# CC1311P3 register map
File version: 1.0
CPU: CM4 1.0, other endian, MPU, FPU, 3 interrupt priority bits
Registers are 32-bit, read-write, reset 0x0 unless marked. A register's access mark holds for its fields unless they carry their own. Offsets are from the block's base; [hi:lo] are bit positions; {n}, {i} and the like mark numbered series; 'fields as' and 'values as' point back to an identical list.

## FLASH — Flash sub-system registers, includes the Flash Memory Controller (FMC), flash read path, and an integrated Efuse controller and EFUSEROM.
Base 0x40030000
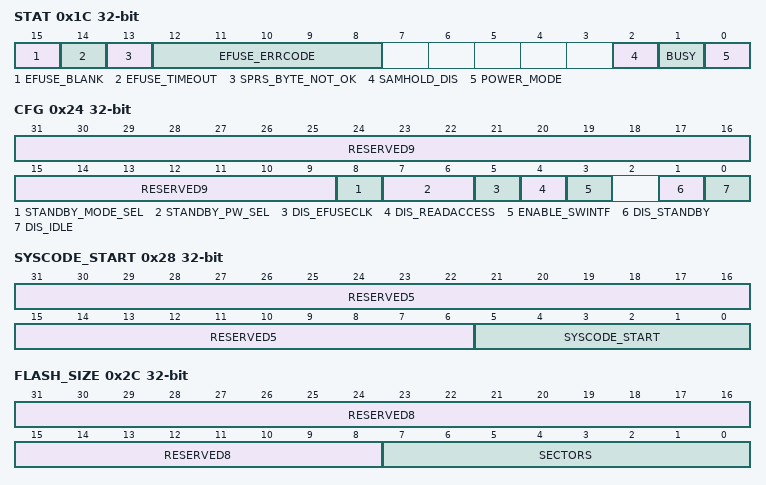
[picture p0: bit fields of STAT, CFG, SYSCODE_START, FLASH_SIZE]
0x1C STAT — FMC and Efuse Status
  [15] EFUSE_BLANK ro — [15:15] Efuse scanning detected if fuse ROM is blank: 0 : Not blank 1 : Blank
  [14] EFUSE_TIMEOUT ro — [14:14] Efuse scanning resulted in timeout error. 0 : No Timeout error 1 : Timeout Error
  [13] SPRS_BYTE_NOT_OK ro — [13:13] Efuse scanning resulted in scan chain Sparse byte error. 0 : No Sparse error 1 : Sparse Error
  [12:8] EFUSE_ERRCODE ro — [12:8] Same as EFUSEERROR.CODE
  [2] SAMHOLD_DIS ro — [2:2] Status indicator of flash sample and hold sequencing logic. This bit will go to 1 some delay after CFG.DIS_IDLE is set to 1. 0: Not disabled 1: Sample and hold disabled and stable
  [1] BUSY ro — [1:1] Fast version of the FMC FMSTAT.BUSY bit. This flag is valid immediately after the operation setting it (FMSTAT.BUSY is delayed some cycles) 0 : Not busy 1 : Busy
  [0] POWER_MODE ro — [0:0] Power state of the flash sub-system. 0 : Active 1 : Low power
0x24 CFG — Internal. Only to be used through TI provided API.
  [31:9] RESERVED9 — [31:9] Internal. Only to be used through TI provided API.
  [8] STANDBY_MODE_SEL — [8:8] Internal. Only to be used through TI provided API.
  [7:6] STANDBY_PW_SEL — [7:6] Internal. Only to be used through TI provided API.
  [5] DIS_EFUSECLK — [5:5] Internal. Only to be used through TI provided API.
  [4] DIS_READACCESS — [4:4] Internal. Only to be used through TI provided API.
  [3] ENABLE_SWINTF — [3:3] Internal. Only to be used through TI provided API.
  [1] DIS_STANDBY — [1:1] Internal. Only to be used through TI provided API.
  [0] DIS_IDLE — [0:0] Internal. Only to be used through TI provided API.
0x28 SYSCODE_START — Internal. Only to be used through TI provided API.
  [31:6] RESERVED5 ro — [31:6] Internal. Only to be used through TI provided API.
  [5:0] SYSCODE_START — [5:0] Internal. Only to be used through TI provided API.
0x2C FLASH_SIZE — Internal. Only to be used through TI provided API.
  [31:8] RESERVED8 ro — [31:8] Internal. Only to be used through TI provided API.
  [7:0] SECTORS — [7:0] Internal. Only to be used through TI provided API.
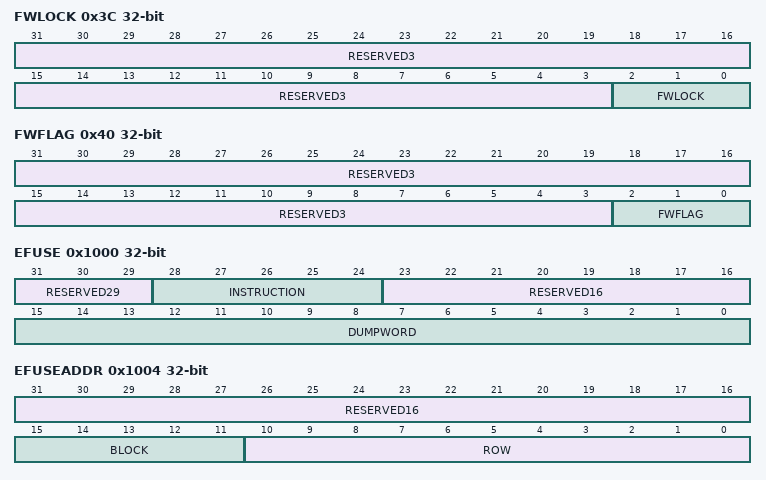
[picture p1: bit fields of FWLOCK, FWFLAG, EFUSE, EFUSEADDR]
0x3C FWLOCK — Internal. Only to be used through TI provided API.
  [31:3] RESERVED3 ro — [31:3] Internal. Only to be used through TI provided API.
  [2:0] FWLOCK — [2:0] Internal. Only to be used through TI provided API.
0x40 FWFLAG — Internal. Only to be used through TI provided API.
  [31:3] RESERVED3 ro — [31:3] Internal. Only to be used through TI provided API.
  [2:0] FWFLAG — [2:0] Internal. Only to be used through TI provided API.
0x1000 EFUSE — Internal. Only to be used through TI provided API.
  [31:29] RESERVED29 ro — [31:29] Internal. Only to be used through TI provided API.
  [28:24] INSTRUCTION — [28:24] Internal. Only to be used through TI provided API.
  [23:16] RESERVED16 ro — [23:16] Internal. Only to be used through TI provided API.
  [15:0] DUMPWORD — [15:0] Internal. Only to be used through TI provided API.
0x1004 EFUSEADDR — Internal. Only to be used through TI provided API.
  [31:16] RESERVED16 ro — [31:16] Internal. Only to be used through TI provided API.
  [15:11] BLOCK — [15:11] Internal. Only to be used through TI provided API.
  [10:0] ROW — [10:0] Internal. Only to be used through TI provided API.
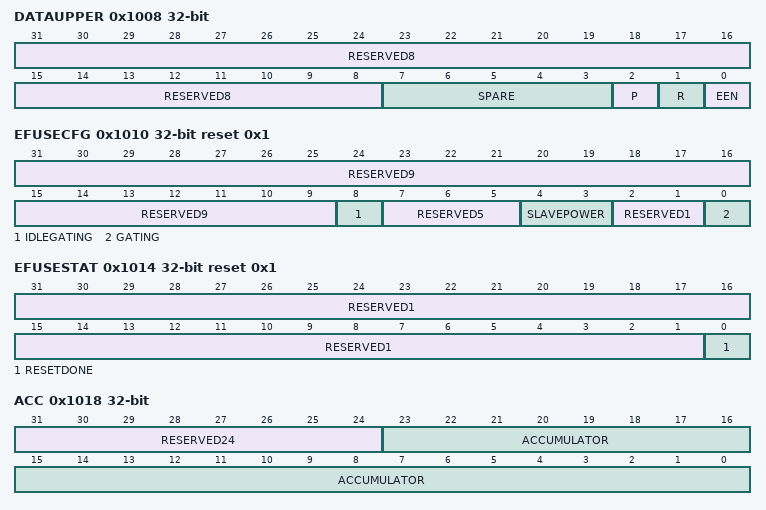
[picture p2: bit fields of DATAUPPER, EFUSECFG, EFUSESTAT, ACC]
0x1008 DATAUPPER — Internal. Only to be used through TI provided API.
  [31:8] RESERVED8 ro — [31:8] Internal. Only to be used through TI provided API.
  [7:3] SPARE — [7:3] Internal. Only to be used through TI provided API.
  [2] P — [2:2] Internal. Only to be used through TI provided API.
  [1] R — [1:1] Internal. Only to be used through TI provided API.
  [0] EEN — [0:0] Internal. Only to be used through TI provided API.
0x100C DATALOWER — Internal. Only to be used through TI provided API.
  [31:0] DATA — [31:0] Internal. Only to be used through TI provided API.
0x1010 EFUSECFG reset 0x1 — Internal. Only to be used through TI provided API.
  [31:9] RESERVED9 ro — [31:9] Internal. Only to be used through TI provided API.
  [8] IDLEGATING — [8:8] Internal. Only to be used through TI provided API.
  [7:5] RESERVED5 ro — [7:5] Internal. Only to be used through TI provided API.
  [4:3] SLAVEPOWER — [4:3] Internal. Only to be used through TI provided API.
  [2:1] RESERVED1 ro — [2:1] Internal. Only to be used through TI provided API.
  [0] GATING — [0:0] Internal. Only to be used through TI provided API.
0x1014 EFUSESTAT reset 0x1 — Internal. Only to be used through TI provided API.
  [31:1] RESERVED1 ro — [31:1] Internal. Only to be used through TI provided API.
  [0] RESETDONE ro — [0:0] Internal. Only to be used through TI provided API.
0x1018 ACC — Internal. Only to be used through TI provided API.
  [31:24] RESERVED24 ro — [31:24] Internal. Only to be used through TI provided API.
  [23:0] ACCUMULATOR ro — [23:0] Internal. Only to be used through TI provided API.
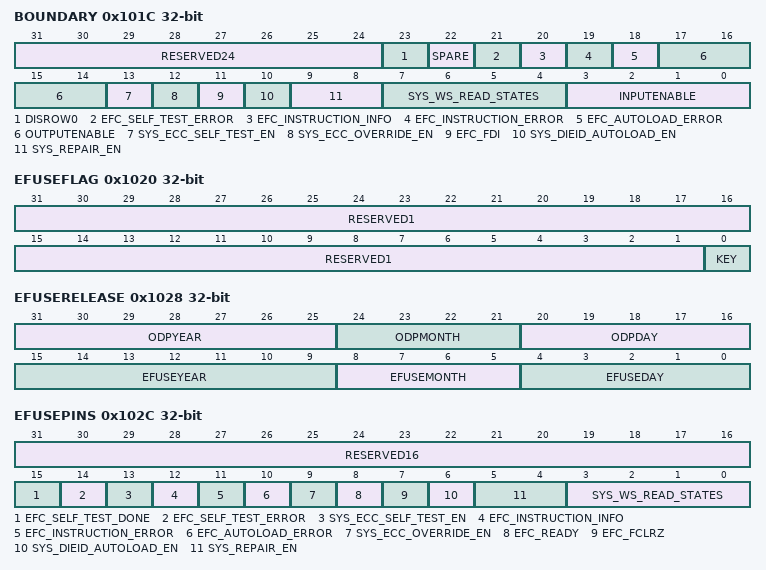
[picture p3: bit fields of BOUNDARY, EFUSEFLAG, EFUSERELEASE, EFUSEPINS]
0x101C BOUNDARY — Internal. Only to be used through TI provided API.
  [31:24] RESERVED24 ro — [31:24] Internal. Only to be used through TI provided API.
  [23] DISROW0 — [23:23] Internal. Only to be used through TI provided API.
  [22] SPARE — [22:22] Internal. Only to be used through TI provided API.
  [21] EFC_SELF_TEST_ERROR — [21:21] Internal. Only to be used through TI provided API.
  [20] EFC_INSTRUCTION_INFO — [20:20] Internal. Only to be used through TI provided API.
  [19] EFC_INSTRUCTION_ERROR — [19:19] Internal. Only to be used through TI provided API.
  [18] EFC_AUTOLOAD_ERROR — [18:18] Internal. Only to be used through TI provided API.
  [17:14] OUTPUTENABLE — [17:14] Internal. Only to be used through TI provided API.
  [13] SYS_ECC_SELF_TEST_EN — [13:13] Internal. Only to be used through TI provided API.
  [12] SYS_ECC_OVERRIDE_EN — [12:12] Internal. Only to be used through TI provided API.
  [11] EFC_FDI — [11:11] Internal. Only to be used through TI provided API.
  [10] SYS_DIEID_AUTOLOAD_EN — [10:10] Internal. Only to be used through TI provided API.
  [9:8] SYS_REPAIR_EN — [9:8] Internal. Only to be used through TI provided API.
  [7:4] SYS_WS_READ_STATES — [7:4] Internal. Only to be used through TI provided API.
  [3:0] INPUTENABLE — [3:0] Internal. Only to be used through TI provided API.
0x1020 EFUSEFLAG — Internal. Only to be used through TI provided API.
  [31:1] RESERVED1 ro — [31:1] Internal. Only to be used through TI provided API.
  [0] KEY ro — [0:0] Internal. Only to be used through TI provided API.
0x1024 EFUSEKEY — Internal. Only to be used through TI provided API.
  [31:0] CODE — [31:0] Internal. Only to be used through TI provided API.
0x1028 EFUSERELEASE — Internal. Only to be used through TI provided API.
  [31:25] ODPYEAR ro — [31:25] Internal. Only to be used through TI provided API.
  [24:21] ODPMONTH ro — [24:21] Internal. Only to be used through TI provided API.
  [20:16] ODPDAY ro — [20:16] Internal. Only to be used through TI provided API.
  [15:9] EFUSEYEAR ro — [15:9] Internal. Only to be used through TI provided API.
  [8:5] EFUSEMONTH ro — [8:5] Internal. Only to be used through TI provided API.
  [4:0] EFUSEDAY ro — [4:0] Internal. Only to be used through TI provided API.
0x102C EFUSEPINS — Internal. Only to be used through TI provided API.
  [31:16] RESERVED16 ro — [31:16] Internal. Only to be used through TI provided API.
  [15] EFC_SELF_TEST_DONE ro — [15:15] Internal. Only to be used through TI provided API.
  [14] EFC_SELF_TEST_ERROR ro — [14:14] Internal. Only to be used through TI provided API.
  [13] SYS_ECC_SELF_TEST_EN ro — [13:13] Internal. Only to be used through TI provided API.
  [12] EFC_INSTRUCTION_INFO ro — [12:12] Internal. Only to be used through TI provided API.
  [11] EFC_INSTRUCTION_ERROR ro — [11:11] Internal. Only to be used through TI provided API.
  [10] EFC_AUTOLOAD_ERROR ro — [10:10] Internal. Only to be used through TI provided API.
  [9] SYS_ECC_OVERRIDE_EN ro — [9:9] Internal. Only to be used through TI provided API.
  [8] EFC_READY ro — [8:8] Internal. Only to be used through TI provided API.
  [7] EFC_FCLRZ ro — [7:7] Internal. Only to be used through TI provided API.
  [6] SYS_DIEID_AUTOLOAD_EN ro — [6:6] Internal. Only to be used through TI provided API.
  [5:4] SYS_REPAIR_EN ro — [5:4] Internal. Only to be used through TI provided API.
  [3:0] SYS_WS_READ_STATES ro — [3:0] Internal. Only to be used through TI provided API.
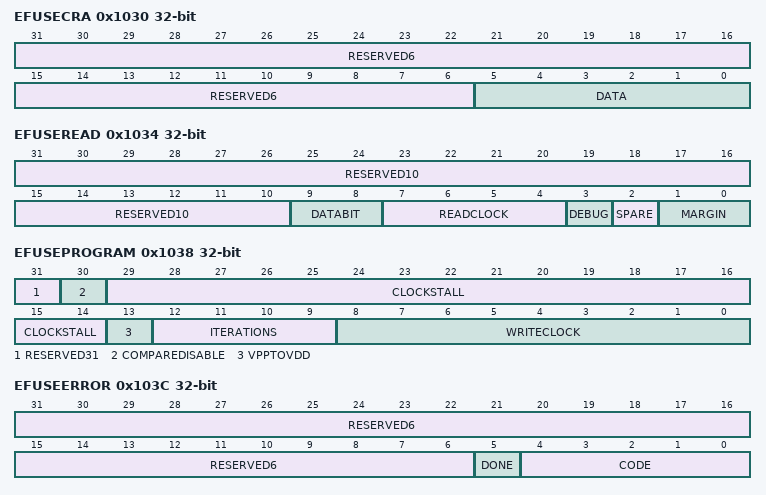
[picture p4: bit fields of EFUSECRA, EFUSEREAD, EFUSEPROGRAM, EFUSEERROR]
0x1030 EFUSECRA — Internal. Only to be used through TI provided API.
  [31:6] RESERVED6 ro — [31:6] Internal. Only to be used through TI provided API.
  [5:0] DATA — [5:0] Internal. Only to be used through TI provided API.
0x1034 EFUSEREAD — Internal. Only to be used through TI provided API.
  [31:10] RESERVED10 ro — [31:10] Internal. Only to be used through TI provided API.
  [9:8] DATABIT — [9:8] Internal. Only to be used through TI provided API.
  [7:4] READCLOCK — [7:4] Internal. Only to be used through TI provided API.
  [3] DEBUG — [3:3] Internal. Only to be used through TI provided API.
  [2] SPARE — [2:2] Internal. Only to be used through TI provided API.
  [1:0] MARGIN — [1:0] Internal. Only to be used through TI provided API.
0x1038 EFUSEPROGRAM — Internal. Only to be used through TI provided API.
  [31] RESERVED31 ro — [31:31] Internal. Only to be used through TI provided API.
  [30] COMPAREDISABLE — [30:30] Internal. Only to be used through TI provided API.
  [29:14] CLOCKSTALL — [29:14] Internal. Only to be used through TI provided API.
  [13] VPPTOVDD — [13:13] Internal. Only to be used through TI provided API.
  [12:9] ITERATIONS — [12:9] Internal. Only to be used through TI provided API.
  [8:0] WRITECLOCK — [8:0] Internal. Only to be used through TI provided API.
0x103C EFUSEERROR — Internal. Only to be used through TI provided API.
  [31:6] RESERVED6 ro — [31:6] Internal. Only to be used through TI provided API.
  [5] DONE — [5:5] Internal. Only to be used through TI provided API.
  [4:0] CODE — [4:0] Internal. Only to be used through TI provided API.
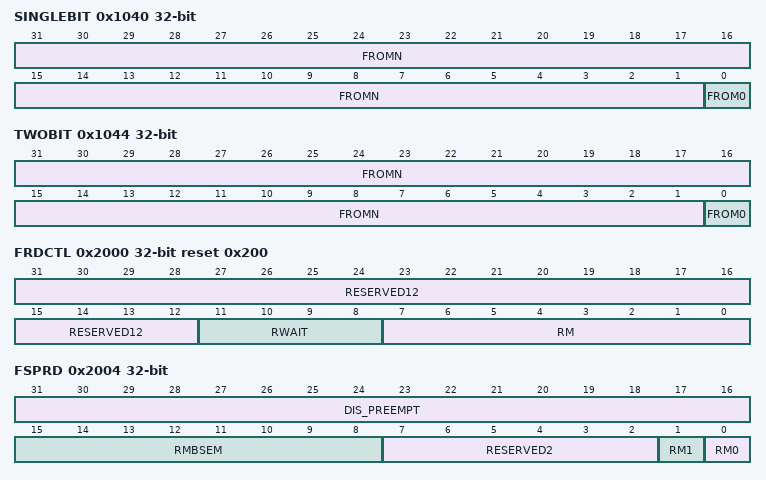
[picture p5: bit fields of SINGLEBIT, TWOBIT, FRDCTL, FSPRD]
0x1040 SINGLEBIT — Internal. Only to be used through TI provided API.
  [31:1] FROMN ro — [31:1] Internal. Only to be used through TI provided API.
  [0] FROM0 ro — [0:0] Internal. Only to be used through TI provided API.
0x1044 TWOBIT — Internal. Only to be used through TI provided API.
  fields as SINGLEBIT
0x1048 SELFTESTCYC — Internal. Only to be used through TI provided API.
  [31:0] CYCLES — [31:0] Internal. Only to be used through TI provided API.
0x104C SELFTESTSIGN — Internal. Only to be used through TI provided API.
  [31:0] SIGNATURE — [31:0] Internal. Only to be used through TI provided API.
0x2000 FRDCTL reset 0x200 — Internal. Only to be used through TI provided API.
  [31:12] RESERVED12 ro — [31:12] Internal. Only to be used through TI provided API.
  [11:8] RWAIT — [11:8] Internal. Only to be used through TI provided API.
  [7:0] RM ro — [7:0] Internal. Only to be used through TI provided API.
0x2004 FSPRD — Internal. Only to be used through TI provided API.
  [31:16] DIS_PREEMPT ro — [31:16] Internal. Only to be used through TI provided API.
  [15:8] RMBSEM — [15:8] Internal. Only to be used through TI provided API.
  [7:2] RESERVED2 ro — [7:2] Internal. Only to be used through TI provided API.
  [1] RM1 — [1:1] Internal. Only to be used through TI provided API.
  [0] RM0 — [0:0] Internal. Only to be used through TI provided API.
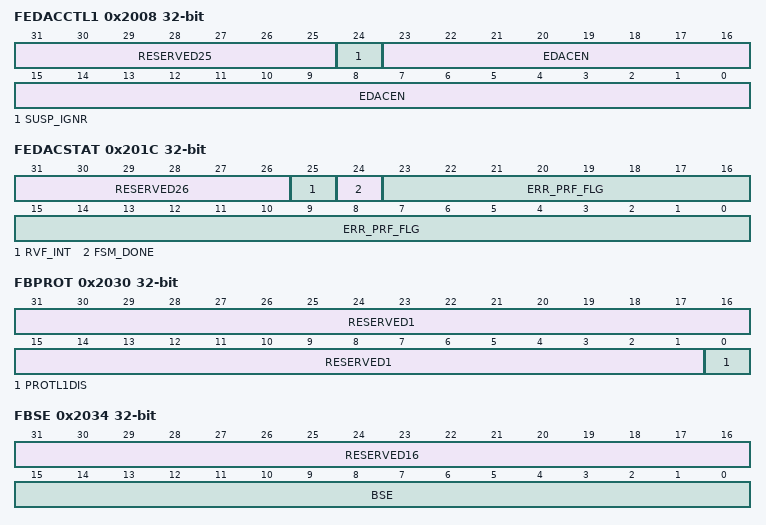
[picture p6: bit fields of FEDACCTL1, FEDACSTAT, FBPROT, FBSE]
0x2008 FEDACCTL1 — Internal. Only to be used through TI provided API.
  [31:25] RESERVED25 ro — [31:25] Internal. Only to be used through TI provided API.
  [24] SUSP_IGNR — [24:24] Internal. Only to be used through TI provided API.
  [23:0] EDACEN ro — [23:0] Internal. Only to be used through TI provided API.
0x200C FEDACCTL2 — Internal. Only to be used through TI provided API.
  [31:0] SEC_THRESHOLD ro — [31:0] Internal. Only to be used through TI provided API.
0x2010 FCOR_ERR_CNT — Internal. Only to be used through TI provided API.
  [31:0] COR_ERR_CNT ro — [31:0] Internal. Only to be used through TI provided API.
0x2014 FCOR_ERR_ADD — Internal. Only to be used through TI provided API.
  [31:0] FCOR_ERR_ADD ro — [31:0] Internal. Only to be used through TI provided API.
0x2018 FCOR_ERR_POS — Internal. Only to be used through TI provided API.
  [31:0] SERR_POS ro — [31:0] Internal. Only to be used through TI provided API.
0x201C FEDACSTAT — Internal. Only to be used through TI provided API.
  [31:26] RESERVED26 ro — [31:26] Internal. Only to be used through TI provided API.
  [25] RVF_INT — [25:25] Internal. Only to be used through TI provided API.
  [24] FSM_DONE — [24:24] Internal. Only to be used through TI provided API.
  [23:0] ERR_PRF_FLG ro — [23:0] Internal. Only to be used through TI provided API.
0x2020 FUNC_ERR_ADD — Internal. Only to be used through TI provided API.
  [31:0] FUNC_ERR_ADD ro — [31:0] Internal. Only to be used through TI provided API.
0x2024 FEDACSDIS — Internal. Only to be used through TI provided API.
  [31:0] SECTORID0 ro — [31:0] Internal. Only to be used through TI provided API.
0x2028 FPRIM_ADD_TAG — Internal. Only to be used through TI provided API.
  [31:0] PRIM_ADD_TAG ro — [31:0] Internal. Only to be used through TI provided API.
0x202C FREDU_ADD_TAG — Internal. Only to be used through TI provided API.
  [31:0] REDU_ADD_TAG ro — [31:0] Internal. Only to be used through TI provided API.
0x2030 FBPROT — Internal. Only to be used through TI provided API.
  [31:1] RESERVED1 ro — [31:1] Internal. Only to be used through TI provided API.
  [0] PROTL1DIS — [0:0] Internal. Only to be used through TI provided API.
0x2034 FBSE — Internal. Only to be used through TI provided API.
  [31:16] RESERVED16 ro — [31:16] Internal. Only to be used through TI provided API.
  [15:0] BSE — [15:0] Internal. Only to be used through TI provided API.
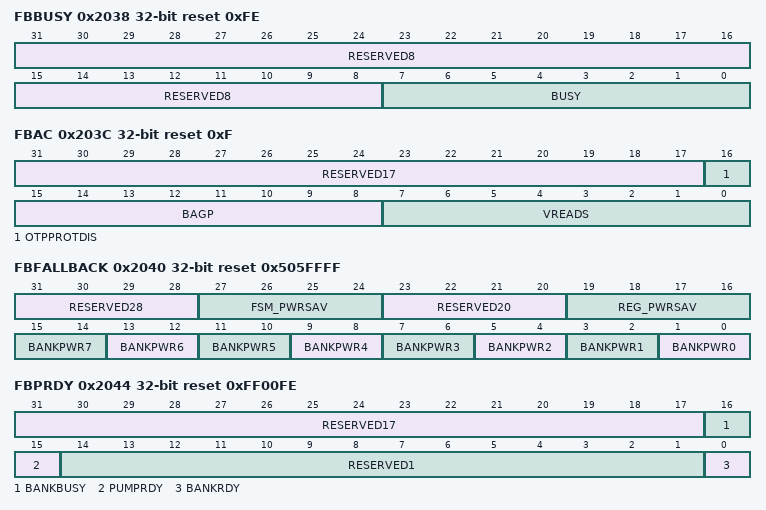
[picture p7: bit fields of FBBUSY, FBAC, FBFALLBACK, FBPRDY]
0x2038 FBBUSY reset 0xFE — Internal. Only to be used through TI provided API.
  [31:8] RESERVED8 ro — [31:8] Internal. Only to be used through TI provided API.
  [7:0] BUSY ro — [7:0] Internal. Only to be used through TI provided API.
0x203C FBAC reset 0xF — Internal. Only to be used through TI provided API.
  [31:17] RESERVED17 ro — [31:17] Internal. Only to be used through TI provided API.
  [16] OTPPROTDIS — [16:16] Internal. Only to be used through TI provided API.
  [15:8] BAGP — [15:8] Internal. Only to be used through TI provided API.
  [7:0] VREADS — [7:0] Internal. Only to be used through TI provided API.
0x2040 FBFALLBACK reset 0x505FFFF — Internal. Only to be used through TI provided API.
  [31:28] RESERVED28 ro — [31:28] Internal. Only to be used through TI provided API.
  [27:24] FSM_PWRSAV — [27:24] Internal. Only to be used through TI provided API.
  [23:20] RESERVED20 ro — [23:20] Internal. Only to be used through TI provided API.
  [19:16] REG_PWRSAV — [19:16] Internal. Only to be used through TI provided API.
  [2n+1:2n] BANKPWR{n} (n=0..7) — [{2n+1}:{2n}] Internal. Only to be used through TI provided API.
0x2044 FBPRDY reset 0xFF00FE — Internal. Only to be used through TI provided API.
  [31:17] RESERVED17 ro — [31:17] Internal. Only to be used through TI provided API.
  [16] BANKBUSY ro — [16:16] Internal. Only to be used through TI provided API.
  [15] PUMPRDY ro — [15:15] Internal. Only to be used through TI provided API.
  [14:1] RESERVED1 ro — [14:1] Internal. Only to be used through TI provided API.
  [0] BANKRDY ro — [0:0] Internal. Only to be used through TI provided API.
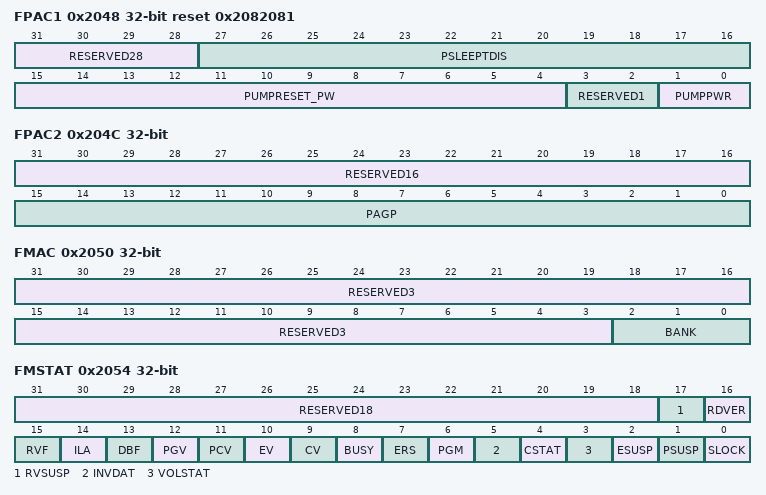
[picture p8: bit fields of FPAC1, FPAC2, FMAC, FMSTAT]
0x2048 FPAC1 reset 0x2082081 — Internal. Only to be used through TI provided API.
  [31:28] RESERVED28 ro — [31:28] Internal. Only to be used through TI provided API.
  [27:16] PSLEEPTDIS — [27:16] Internal. Only to be used through TI provided API.
  [15:4] PUMPRESET_PW — [15:4] Internal. Only to be used through TI provided API.
  [3:2] RESERVED1 ro — [3:2] Internal. Only to be used through TI provided API.
  [1:0] PUMPPWR — [1:0] Internal. Only to be used through TI provided API.
0x204C FPAC2 — Internal. Only to be used through TI provided API.
  [31:16] RESERVED16 ro — [31:16] Internal. Only to be used through TI provided API.
  [15:0] PAGP — [15:0] Internal. Only to be used through TI provided API.
0x2050 FMAC — Internal. Only to be used through TI provided API.
  [31:3] RESERVED3 ro — [31:3] Internal. Only to be used through TI provided API.
  [2:0] BANK — [2:0] Internal. Only to be used through TI provided API.
0x2054 FMSTAT — Internal. Only to be used through TI provided API.
  [31:18] RESERVED18 ro — [31:18] Internal. Only to be used through TI provided API.
  [17] RVSUSP ro — [17:17] Internal. Only to be used through TI provided API.
  [16] RDVER ro — [16:16] Internal. Only to be used through TI provided API.
  [15] RVF ro — [15:15] Internal. Only to be used through TI provided API.
  [14] ILA ro — [14:14] Internal. Only to be used through TI provided API.
  [13] DBF ro — [13:13] Internal. Only to be used through TI provided API.
  [12] PGV ro — [12:12] Internal. Only to be used through TI provided API.
  [11] PCV ro — [11:11] Internal. Only to be used through TI provided API.
  [10] EV ro — [10:10] Internal. Only to be used through TI provided API.
  [9] CV ro — [9:9] Internal. Only to be used through TI provided API.
  [8] BUSY ro — [8:8] Internal. Only to be used through TI provided API.
  [7] ERS ro — [7:7] Internal. Only to be used through TI provided API.
  [6] PGM ro — [6:6] Internal. Only to be used through TI provided API.
  [5] INVDAT ro — [5:5] Internal. Only to be used through TI provided API.
  [4] CSTAT ro — [4:4] Internal. Only to be used through TI provided API.
  [3] VOLSTAT ro — [3:3] Internal. Only to be used through TI provided API.
  [2] ESUSP ro — [2:2] Internal. Only to be used through TI provided API.
  [1] PSUSP ro — [1:1] Internal. Only to be used through TI provided API.
  [0] SLOCK ro — [0:0] Internal. Only to be used through TI provided API.
0x2058 FEMU_DMSW — Internal. Only to be used through TI provided API.
  [31:0] FEMU_DMSW — [31:0] Internal. Only to be used through TI provided API.
0x205C FEMU_DLSW — Internal. Only to be used through TI provided API.
  [31:0] FEMU_DLSW — [31:0] Internal. Only to be used through TI provided API.
0x2060 FEMU_ECC — Internal. Only to be used through TI provided API.
  [31:0] EMU_ECC — [31:0] Internal. Only to be used through TI provided API.
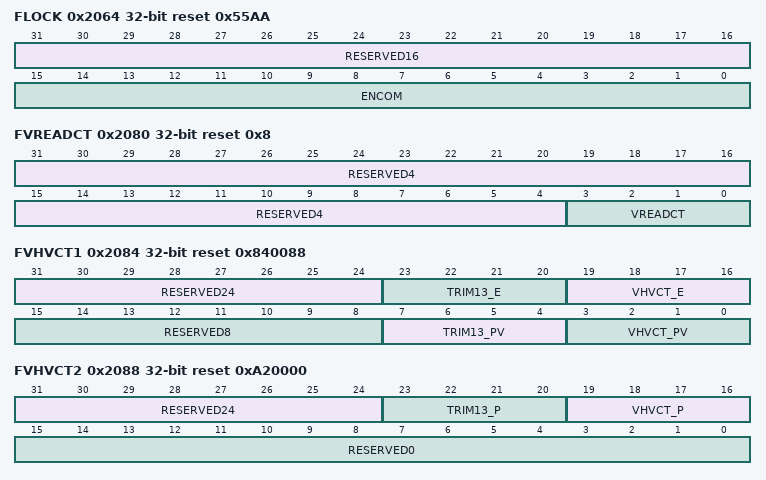
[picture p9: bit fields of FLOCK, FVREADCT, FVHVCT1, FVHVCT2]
0x2064 FLOCK reset 0x55AA — Internal. Only to be used through TI provided API.
  [31:16] RESERVED16 ro — [31:16] Internal. Only to be used through TI provided API.
  [15:0] ENCOM — [15:0] Internal. Only to be used through TI provided API.
0x2068 FEMU_ADDR — Internal. Only to be used through TI provided API.
  [31:0] EMU_ADDR — [31:0] Internal. Only to be used through TI provided API.
0x206C FDIAGCTL — Internal. Only to be used through TI provided API.
  [31:0] DIAGMODE — [31:0] Internal. Only to be used through TI provided API.
0x2070 FRAW_DATAH — Internal. Only to be used through TI provided API.
  [31:0] FRAW_DATAH — [31:0] Internal. Only to be used through TI provided API.
0x2074 FRAW_DATAL — Internal. Only to be used through TI provided API.
  [31:0] FRAW_DATAL — [31:0] Internal. Only to be used through TI provided API.
0x2078 FRAW_ECC — Internal. Only to be used through TI provided API.
  [31:0] RAW_ECC — [31:0] Internal. Only to be used through TI provided API.
0x207C FPAR_OVR — Internal. Only to be used through TI provided API.
  [31:0] DAT_INV_PAR — [31:0] Internal. Only to be used through TI provided API.
0x2080 FVREADCT reset 0x8 — Internal. Only to be used through TI provided API.
  [31:4] RESERVED4 ro — [31:4] Internal. Only to be used through TI provided API.
  [3:0] VREADCT — [3:0] Internal. Only to be used through TI provided API.
0x2084 FVHVCT1 reset 0x840088 — Internal. Only to be used through TI provided API.
  [31:24] RESERVED24 ro — [31:24] Internal. Only to be used through TI provided API.
  [23:20] TRIM13_E — [23:20] Internal. Only to be used through TI provided API.
  [19:16] VHVCT_E — [19:16] Internal. Only to be used through TI provided API.
  [15:8] RESERVED8 ro — [15:8] Internal. Only to be used through TI provided API.
  [7:4] TRIM13_PV — [7:4] Internal. Only to be used through TI provided API.
  [3:0] VHVCT_PV — [3:0] Internal. Only to be used through TI provided API.
0x2088 FVHVCT2 reset 0xA20000 — Internal. Only to be used through TI provided API.
  [31:24] RESERVED24 ro — [31:24] Internal. Only to be used through TI provided API.
  [23:20] TRIM13_P — [23:20] Internal. Only to be used through TI provided API.
  [19:16] VHVCT_P — [19:16] Internal. Only to be used through TI provided API.
  [15:0] RESERVED0 ro — [15:0] Internal. Only to be used through TI provided API.
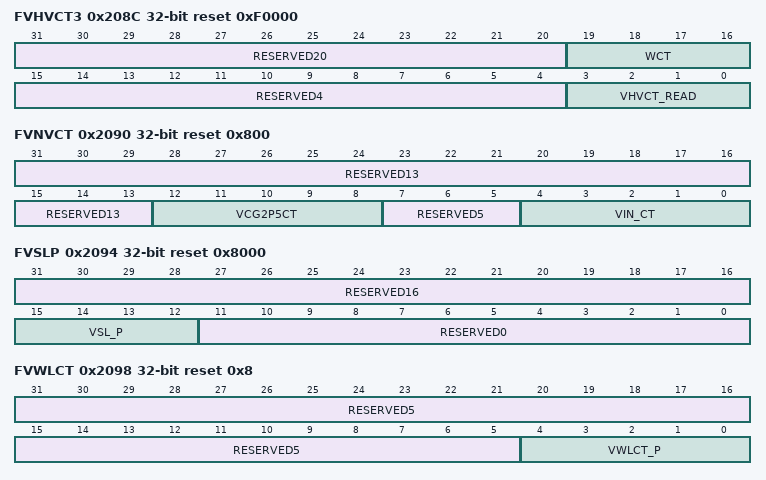
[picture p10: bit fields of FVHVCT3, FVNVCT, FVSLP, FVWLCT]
0x208C FVHVCT3 reset 0xF0000 — Internal. Only to be used through TI provided API.
  [31:20] RESERVED20 ro — [31:20] Internal. Only to be used through TI provided API.
  [19:16] WCT — [19:16] Internal. Only to be used through TI provided API.
  [15:4] RESERVED4 ro — [15:4] Internal. Only to be used through TI provided API.
  [3:0] VHVCT_READ — [3:0] Internal. Only to be used through TI provided API.
0x2090 FVNVCT reset 0x800 — Internal. Only to be used through TI provided API.
  [31:13] RESERVED13 ro — [31:13] Internal. Only to be used through TI provided API.
  [12:8] VCG2P5CT — [12:8] Internal. Only to be used through TI provided API.
  [7:5] RESERVED5 ro — [7:5] Internal. Only to be used through TI provided API.
  [4:0] VIN_CT — [4:0] Internal. Only to be used through TI provided API.
0x2094 FVSLP reset 0x8000 — Internal. Only to be used through TI provided API.
  [31:16] RESERVED16 ro — [31:16] Internal. Only to be used through TI provided API.
  [15:12] VSL_P — [15:12] Internal. Only to be used through TI provided API.
  [11:0] RESERVED0 ro — [11:0] Internal. Only to be used through TI provided API.
0x2098 FVWLCT reset 0x8 — Internal. Only to be used through TI provided API.
  [31:5] RESERVED5 ro — [31:5] Internal. Only to be used through TI provided API.
  [4:0] VWLCT_P — [4:0] Internal. Only to be used through TI provided API.
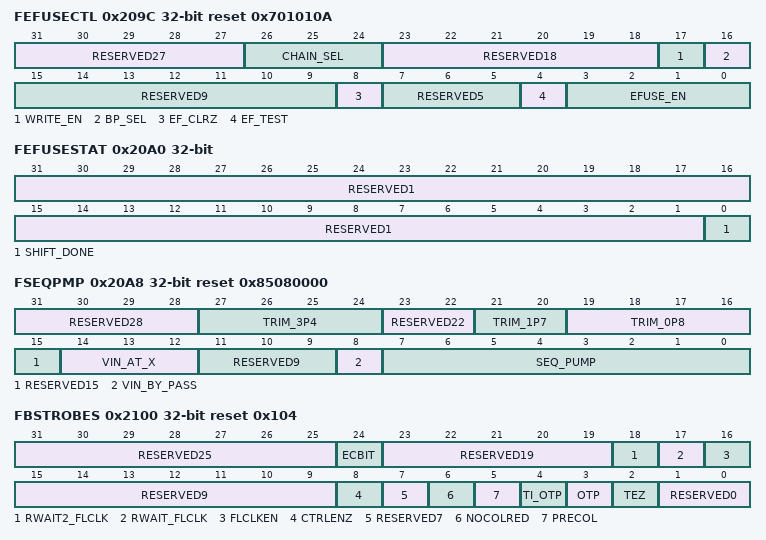
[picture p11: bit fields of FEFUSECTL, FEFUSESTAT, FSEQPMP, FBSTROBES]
0x209C FEFUSECTL reset 0x701010A — Internal. Only to be used through TI provided API.
  [31:27] RESERVED27 ro — [31:27] Internal. Only to be used through TI provided API.
  [26:24] CHAIN_SEL — [26:24] Internal. Only to be used through TI provided API.
  [23:18] RESERVED18 ro — [23:18] Internal. Only to be used through TI provided API.
  [17] WRITE_EN — [17:17] Internal. Only to be used through TI provided API.
  [16] BP_SEL — [16:16] Internal. Only to be used through TI provided API.
  [15:9] RESERVED9 ro — [15:9] Internal. Only to be used through TI provided API.
  [8] EF_CLRZ — [8:8] Internal. Only to be used through TI provided API.
  [7:5] RESERVED5 ro — [7:5] Internal. Only to be used through TI provided API.
  [4] EF_TEST — [4:4] Internal. Only to be used through TI provided API.
  [3:0] EFUSE_EN — [3:0] Internal. Only to be used through TI provided API.
0x20A0 FEFUSESTAT — Internal. Only to be used through TI provided API.
  [31:1] RESERVED1 ro — [31:1] Internal. Only to be used through TI provided API.
  [0] SHIFT_DONE — [0:0] Internal. Only to be used through TI provided API.
0x20A4 FEFUSEDATA — Internal. Only to be used through TI provided API.
  [31:0] FEFUSEDATA — [31:0] Internal. Only to be used through TI provided API.
0x20A8 FSEQPMP reset 0x85080000 — Internal. Only to be used through TI provided API.
  [31:28] RESERVED28 — [31:28] Internal. Only to be used through TI provided API.
  [27:24] TRIM_3P4 — [27:24] Internal. Only to be used through TI provided API.
  [23:22] RESERVED22 ro — [23:22] Internal. Only to be used through TI provided API.
  [21:20] TRIM_1P7 — [21:20] Internal. Only to be used through TI provided API.
  [19:16] TRIM_0P8 — [19:16] Internal. Only to be used through TI provided API.
  [15] RESERVED15 ro — [15:15] Internal. Only to be used through TI provided API.
  [14:12] VIN_AT_X — [14:12] Internal. Only to be used through TI provided API.
  [11:9] RESERVED9 ro — [11:9] Internal. Only to be used through TI provided API.
  [8] VIN_BY_PASS — [8:8] Internal. Only to be used through TI provided API.
  [7:0] SEQ_PUMP — [7:0] Internal. Only to be used through TI provided API.
0x20AC FCLKTRIM — Internal. Only to be used through TI provided API.
  [31:0] TRIM_EN — [31:0] Internal. Only to be used through TI provided API.
0x20B0 ROM_TEST — Internal. Only to be used through TI provided API.
  [31:0] ROM_KEY — [31:0] Internal. Only to be used through TI provided API.
0x20C0 FEDACSDIS2 — Internal. Only to be used through TI provided API.
  [31:0] SECTORID2 — [31:0] Internal. Only to be used through TI provided API.
0x2100 FBSTROBES reset 0x104 — Internal. Only to be used through TI provided API.
  [31:25] RESERVED25 ro — [31:25] Internal. Only to be used through TI provided API.
  [24] ECBIT — [24:24] Internal. Only to be used through TI provided API.
  [23:19] RESERVED19 ro — [23:19] Internal. Only to be used through TI provided API.
  [18] RWAIT2_FLCLK — [18:18] Internal. Only to be used through TI provided API.
  [17] RWAIT_FLCLK — [17:17] Internal. Only to be used through TI provided API.
  [16] FLCLKEN — [16:16] Internal. Only to be used through TI provided API.
  [15:9] RESERVED9 ro — [15:9] Internal. Only to be used through TI provided API.
  [8] CTRLENZ — [8:8] Internal. Only to be used through TI provided API.
  [7] RESERVED7 ro — [7:7] Internal. Only to be used through TI provided API.
  [6] NOCOLRED — [6:6] Internal. Only to be used through TI provided API.
  [5] PRECOL — [5:5] Internal. Only to be used through TI provided API.
  [4] TI_OTP — [4:4] Internal. Only to be used through TI provided API.
  [3] OTP — [3:3] Internal. Only to be used through TI provided API.
  [2] TEZ — [2:2] Internal. Only to be used through TI provided API.
  [1:0] RESERVED0 ro — [1:0] Internal. Only to be used through TI provided API.
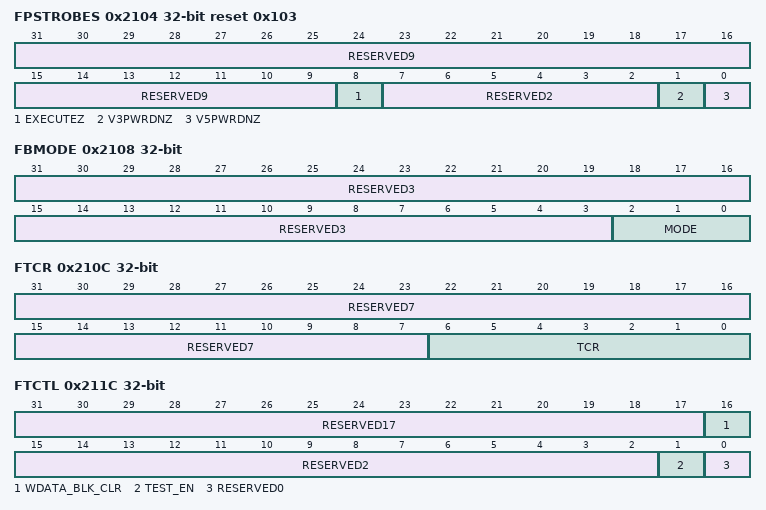
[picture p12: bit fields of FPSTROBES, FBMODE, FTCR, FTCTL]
0x2104 FPSTROBES reset 0x103 — Internal. Only to be used through TI provided API.
  [31:9] RESERVED9 ro — [31:9] Internal. Only to be used through TI provided API.
  [8] EXECUTEZ — [8:8] Internal. Only to be used through TI provided API.
  [7:2] RESERVED2 ro — [7:2] Internal. Only to be used through TI provided API.
  [1] V3PWRDNZ — [1:1] Internal. Only to be used through TI provided API.
  [0] V5PWRDNZ — [0:0] Internal. Only to be used through TI provided API.
0x2108 FBMODE — Internal. Only to be used through TI provided API.
  [31:3] RESERVED3 ro — [31:3] Internal. Only to be used through TI provided API.
  [2:0] MODE — [2:0] Internal. Only to be used through TI provided API.
0x210C FTCR — Internal. Only to be used through TI provided API.
  [31:7] RESERVED7 ro — [31:7] Internal. Only to be used through TI provided API.
  [6:0] TCR — [6:0] Internal. Only to be used through TI provided API.
0x2110 FADDR — Internal. Only to be used through TI provided API.
  [31:0] FADDR — [31:0] Internal. Only to be used through TI provided API.
0x2114 FPMTCTL — Internal. Only to be used through TI provided API.
  [31:0] ADDR_INCR ro — [31:0] Internal. Only to be used through TI provided API.
0x2118 PBISTCTL — Internal. Only to be used through TI provided API.
  [31:0] PBIST_KEY ro — [31:0] Internal. Only to be used through TI provided API.
0x211C FTCTL — Internal. Only to be used through TI provided API.
  [31:17] RESERVED17 ro — [31:17] Internal. Only to be used through TI provided API.
  [16] WDATA_BLK_CLR — [16:16] Internal. Only to be used through TI provided API.
  [15:2] RESERVED2 ro — [15:2] Internal. Only to be used through TI provided API.
  [1] TEST_EN — [1:1] Internal. Only to be used through TI provided API.
  [0] RESERVED0 ro — [0:0] Internal. Only to be used through TI provided API.
{0x2120+4i} FWPWRITE{i} reset 0xFFFFFFFF (i=0..7) — Internal. Only to be used through TI provided API.
  [31:0] FWPWRITE{i} — [31:0] Internal. Only to be used through TI provided API.
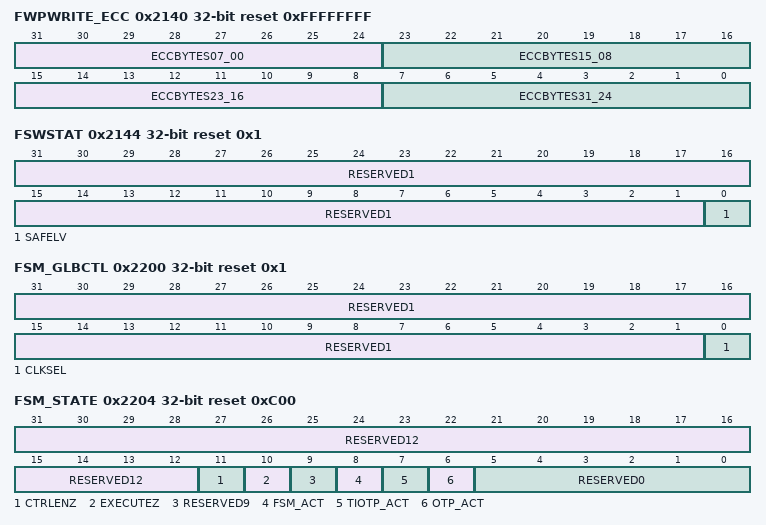
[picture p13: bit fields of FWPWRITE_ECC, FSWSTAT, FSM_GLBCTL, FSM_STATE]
0x2140 FWPWRITE_ECC reset 0xFFFFFFFF — Internal. Only to be used through TI provided API.
  [31:24] ECCBYTES07_00 — [31:24] Internal. Only to be used through TI provided API.
  [23:16] ECCBYTES15_08 — [23:16] Internal. Only to be used through TI provided API.
  [15:8] ECCBYTES23_16 — [15:8] Internal. Only to be used through TI provided API.
  [7:0] ECCBYTES31_24 — [7:0] Internal. Only to be used through TI provided API.
0x2144 FSWSTAT reset 0x1 — Internal. Only to be used through TI provided API.
  [31:1] RESERVED1 ro — [31:1] Internal. Only to be used through TI provided API.
  [0] SAFELV ro — [0:0] Internal. Only to be used through TI provided API.
0x2200 FSM_GLBCTL reset 0x1 — Internal. Only to be used through TI provided API.
  [31:1] RESERVED1 ro — [31:1] Internal. Only to be used through TI provided API.
  [0] CLKSEL ro — [0:0] Internal. Only to be used through TI provided API.
0x2204 FSM_STATE reset 0xC00 — Internal. Only to be used through TI provided API.
  [31:12] RESERVED12 ro — [31:12] Internal. Only to be used through TI provided API.
  [11] CTRLENZ ro — [11:11] Internal. Only to be used through TI provided API.
  [10] EXECUTEZ ro — [10:10] Internal. Only to be used through TI provided API.
  [9] RESERVED9 ro — [9:9] Internal. Only to be used through TI provided API.
  [8] FSM_ACT ro — [8:8] Internal. Only to be used through TI provided API.
  [7] TIOTP_ACT ro — [7:7] Internal. Only to be used through TI provided API.
  [6] OTP_ACT ro — [6:6] Internal. Only to be used through TI provided API.
  [5:0] RESERVED0 ro — [5:0] Internal. Only to be used through TI provided API.
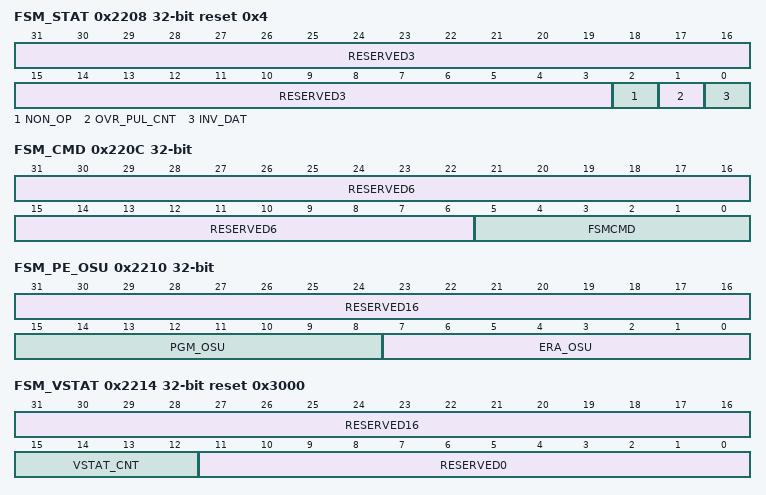
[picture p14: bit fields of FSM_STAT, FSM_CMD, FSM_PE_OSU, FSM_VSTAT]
0x2208 FSM_STAT reset 0x4 — Internal. Only to be used through TI provided API.
  [31:3] RESERVED3 ro — [31:3] Internal. Only to be used through TI provided API.
  [2] NON_OP ro — [2:2] Internal. Only to be used through TI provided API.
  [1] OVR_PUL_CNT ro — [1:1] Internal. Only to be used through TI provided API.
  [0] INV_DAT ro — [0:0] Internal. Only to be used through TI provided API.
0x220C FSM_CMD — Internal. Only to be used through TI provided API.
  [31:6] RESERVED6 ro — [31:6] Internal. Only to be used through TI provided API.
  [5:0] FSMCMD — [5:0] Internal. Only to be used through TI provided API.
0x2210 FSM_PE_OSU — Internal. Only to be used through TI provided API.
  [31:16] RESERVED16 ro — [31:16] Internal. Only to be used through TI provided API.
  [15:8] PGM_OSU — [15:8] Internal. Only to be used through TI provided API.
  [7:0] ERA_OSU — [7:0] Internal. Only to be used through TI provided API.
0x2214 FSM_VSTAT reset 0x3000 — Internal. Only to be used through TI provided API.
  [31:16] RESERVED16 ro — [31:16] Internal. Only to be used through TI provided API.
  [15:12] VSTAT_CNT — [15:12] Internal. Only to be used through TI provided API.
  [11:0] RESERVED0 ro — [11:0] Internal. Only to be used through TI provided API.
0x2218 FSM_PE_VSU — Internal. Only to be used through TI provided API.
  [31:16] RESERVED16 ro — [31:16] Internal. Only to be used through TI provided API.
  [15:8] PGM_VSU — [15:8] Internal. Only to be used through TI provided API.
  [7:0] ERA_VSU — [7:0] Internal. Only to be used through TI provided API.
0x221C FSM_CMP_VSU — Internal. Only to be used through TI provided API.
  [31:16] RESERVED16 ro — [31:16] Internal. Only to be used through TI provided API.
  [15:12] ADD_EXZ — [15:12] Internal. Only to be used through TI provided API.
  [11:0] RESERVED0 ro — [11:0] Internal. Only to be used through TI provided API.
0x2220 FSM_EX_VAL reset 0x301 — Internal. Only to be used through TI provided API.
  [31:16] RESERVED16 ro — [31:16] Internal. Only to be used through TI provided API.
  [15:8] REP_VSU — [15:8] Internal. Only to be used through TI provided API.
  [7:0] EXE_VALD — [7:0] Internal. Only to be used through TI provided API.
0x2224 FSM_RD_H reset 0x5A — Internal. Only to be used through TI provided API.
  [31:8] RESERVED8 ro — [31:8] Internal. Only to be used through TI provided API.
  [7:0] RD_H — [7:0] Internal. Only to be used through TI provided API.
0x2228 FSM_P_OH reset 0x100 — Internal. Only to be used through TI provided API.
  [31:16] RESERVED16 ro — [31:16] Internal. Only to be used through TI provided API.
  [15:8] PGM_OH — [15:8] Internal. Only to be used through TI provided API.
  [7:0] RESERVED0 ro — [7:0] Internal. Only to be used through TI provided API.
0x222C FSM_ERA_OH reset 0x1 — Internal. Only to be used through TI provided API.
  [31:16] RESERVED16 ro — [31:16] Internal. Only to be used through TI provided API.
  [15:0] ERA_OH — [15:0] Internal. Only to be used through TI provided API.
0x2230 FSM_SAV_PPUL — Internal. Only to be used through TI provided API.
  [31:12] RESERVED12 ro — [31:12] Internal. Only to be used through TI provided API.
  [11:0] SAV_P_PUL ro — [11:0] Internal. Only to be used through TI provided API.
0x2234 FSM_PE_VH reset 0x100 — Internal. Only to be used through TI provided API.
  [31:16] RESERVED16 ro — [31:16] Internal. Only to be used through TI provided API.
  [15:8] PGM_VH — [15:8] Internal. Only to be used through TI provided API.
  [7:0] ERA_VH ro — [7:0] Internal. Only to be used through TI provided API.
0x2240 FSM_PRG_PW — Internal. Only to be used through TI provided API.
  [31:16] RESERVED16 ro — [31:16] Internal. Only to be used through TI provided API.
  [15:0] PROG_PUL_WIDTH — [15:0] Internal. Only to be used through TI provided API.
0x2244 FSM_ERA_PW — Internal. Only to be used through TI provided API.
  [31:0] FSM_ERA_PW — [31:0] Internal. Only to be used through TI provided API.
0x2254 FSM_SAV_ERA_PUL — Internal. Only to be used through TI provided API.
  [31:12] RESERVED12 ro — [31:12] Internal. Only to be used through TI provided API.
  [11:0] SAV_ERA_PUL ro — [11:0] Internal. Only to be used through TI provided API.
0x2258 FSM_TIMER — Internal. Only to be used through TI provided API.
  [31:0] FSM_TIMER ro — [31:0] Internal. Only to be used through TI provided API.
0x225C FSM_MODE — Internal. Only to be used through TI provided API.
  [31:20] RESERVED20 ro — [31:20] Internal. Only to be used through TI provided API.
  [19:18] RDV_SUBMODE ro — [19:18] Internal. Only to be used through TI provided API.
  [17:16] PGM_SUBMODE ro — [17:16] Internal. Only to be used through TI provided API.
  [15:14] ERA_SUBMODE ro — [15:14] Internal. Only to be used through TI provided API.
  [13:12] SUBMODE ro — [13:12] Internal. Only to be used through TI provided API.
  [11:9] SAV_PGM_CMD ro — [11:9] Internal. Only to be used through TI provided API.
  [8:6] SAV_ERA_MODE ro — [8:6] Internal. Only to be used through TI provided API.
  [5:3] MODE ro — [5:3] Internal. Only to be used through TI provided API.
  [2:0] CMD ro — [2:0] Internal. Only to be used through TI provided API.
0x2260 FSM_PGM — Internal. Only to be used through TI provided API.
  [31:26] RESERVED26 ro — [31:26] Internal. Only to be used through TI provided API.
  [25:23] PGM_BANK ro — [25:23] Internal. Only to be used through TI provided API.
  [22:0] PGM_ADDR ro — [22:0] Internal. Only to be used through TI provided API.
0x2264 FSM_ERA — Internal. Only to be used through TI provided API.
  [31:26] RESERVED26 ro — [31:26] Internal. Only to be used through TI provided API.
  [25:23] ERA_BANK ro — [25:23] Internal. Only to be used through TI provided API.
  [22:0] ERA_ADDR ro — [22:0] Internal. Only to be used through TI provided API.
0x2268 FSM_PRG_PUL reset 0x40032 — Internal. Only to be used through TI provided API.
  [31:20] RESERVED20 ro — [31:20] Internal. Only to be used through TI provided API.
  [19:16] BEG_EC_LEVEL — [19:16] Internal. Only to be used through TI provided API.
  [15:12] RESERVED12 ro — [15:12] Internal. Only to be used through TI provided API.
  [11:0] MAX_PRG_PUL — [11:0] Internal. Only to be used through TI provided API.
0x226C FSM_ERA_PUL reset 0x40BB8 — Internal. Only to be used through TI provided API.
  [31:20] RESERVED20 ro — [31:20] Internal. Only to be used through TI provided API.
  [19:16] MAX_EC_LEVEL — [19:16] Internal. Only to be used through TI provided API.
  [15:12] RESERVED12 ro — [15:12] Internal. Only to be used through TI provided API.
  [11:0] MAX_ERA_PUL — [11:0] Internal. Only to be used through TI provided API.
0x2270 FSM_STEP_SIZE — Internal. Only to be used through TI provided API.
  [31:25] RESERVED25 ro — [31:25] Internal. Only to be used through TI provided API.
  [24:16] EC_STEP_SIZE — [24:16] Internal. Only to be used through TI provided API.
  [15:0] RESERVED0 ro — [15:0] Internal. Only to be used through TI provided API.
0x2274 FSM_PUL_CNTR — Internal. Only to be used through TI provided API.
  [31:25] RESERVED25 ro — [31:25] Internal. Only to be used through TI provided API.
  [24:16] CUR_EC_LEVEL ro — [24:16] Internal. Only to be used through TI provided API.
  [15:12] RESERVED12 ro — [15:12] Internal. Only to be used through TI provided API.
  [11:0] PUL_CNTR ro — [11:0] Internal. Only to be used through TI provided API.
0x2278 FSM_EC_STEP_HEIGHT — Internal. Only to be used through TI provided API.
  [31:4] RESERVED4 ro — [31:4] Internal. Only to be used through TI provided API.
  [3:0] EC_STEP_HEIGHT — [3:0] Internal. Only to be used through TI provided API.
0x227C FSM_ST_MACHINE reset 0x800500 — Internal. Only to be used through TI provided API.
  [31:24] RESERVED24 ro — [31:24] Internal. Only to be used through TI provided API.
  [23] DO_PRECOND — [23:23] Internal. Only to be used through TI provided API.
  [22] FSM_INT_EN — [22:22] Internal. Only to be used through TI provided API.
  [21] ALL_BANKS — [21:21] Internal. Only to be used through TI provided API.
  [20] CMPV_ALLOWED — [20:20] Internal. Only to be used through TI provided API.
  [19] RANDOM — [19:19] Internal. Only to be used through TI provided API.
  [18] RV_SEC_EN — [18:18] Internal. Only to be used through TI provided API.
  [17] RV_RES — [17:17] Internal. Only to be used through TI provided API.
  [16] RV_INT_EN — [16:16] Internal. Only to be used through TI provided API.
  [15] RESERVED15 ro — [15:15] Internal. Only to be used through TI provided API.
  [14] ONE_TIME_GOOD — [14:14] Internal. Only to be used through TI provided API.
  [13:12] RESERVED12 ro — [13:12] Internal. Only to be used through TI provided API.
  [11] DO_REDU_COL — [11:11] Internal. Only to be used through TI provided API.
  [10:7] DBG_SHORT_ROW — [10:7] Internal. Only to be used through TI provided API.
  [6] RESERVED6 ro — [6:6] Internal. Only to be used through TI provided API.
  [5] PGM_SEC_COF_EN — [5:5] Internal. Only to be used through TI provided API.
  [4] PREC_STOP_EN — [4:4] Internal. Only to be used through TI provided API.
  [3] DIS_TST_EN — [3:3] Internal. Only to be used through TI provided API.
  [2] CMD_EN — [2:2] Internal. Only to be used through TI provided API.
  [1] INV_DATA — [1:1] Internal. Only to be used through TI provided API.
  [0] OVERRIDE — [0:0] Internal. Only to be used through TI provided API.
0x2280 FSM_FLES — Internal. Only to be used through TI provided API.
  [31:12] RESERVED12 ro — [31:12] Internal. Only to be used through TI provided API.
  [11:8] BLK_TIOTP — [11:8] Internal. Only to be used through TI provided API.
  [7:0] BLK_OTP — [7:0] Internal. Only to be used through TI provided API.
0x2288 FSM_WR_ENA reset 0x2 — Internal. Only to be used through TI provided API.
  [31:3] RESERVED3 ro — [31:3] Internal. Only to be used through TI provided API.
  [2:0] WR_ENA — [2:0] Internal. Only to be used through TI provided API.
0x228C FSM_ACC_PP — Internal. Only to be used through TI provided API.
  [31:0] FSM_ACC_PP ro — [31:0] Internal. Only to be used through TI provided API.
0x2290 FSM_ACC_EP — Internal. Only to be used through TI provided API.
  [31:16] RESERVED16 ro — [31:16] Internal. Only to be used through TI provided API.
  [15:0] ACC_EP ro — [15:0] Internal. Only to be used through TI provided API.
0x22A0 FSM_ADDR — Internal. Only to be used through TI provided API.
  [31] RESERVED31 ro — [31:31] Internal. Only to be used through TI provided API.
  [30:28] BANK ro — [30:28] Internal. Only to be used through TI provided API.
  [27:0] CUR_ADDR ro — [27:0] Internal. Only to be used through TI provided API.
0x22A4 FSM_SECTOR reset 0xFFFF0000 — Internal. Only to be used through TI provided API.
  [31:16] SECT_ERASED — [31:16] Internal. Only to be used through TI provided API.
  [15:8] FSM_SECTOR_EXTENSION ro — [15:8] Internal. Only to be used through TI provided API.
  [7:4] SECTOR ro — [7:4] Internal. Only to be used through TI provided API.
  [3:0] SEC_OUT ro — [3:0] Internal. Only to be used through TI provided API.
0x22A8 FMC_REV_ID — Internal. Only to be used through TI provided API.
  [31:12] MOD_VERSION ro — [31:12] Internal. Only to be used through TI provided API.
  [11:0] CONFIG_CRC ro — [11:0] Internal. Only to be used through TI provided API.
0x22AC FSM_ERR_ADDR — Internal. Only to be used through TI provided API.
  [31] RESERVED31 ro — [31:31] Internal. Only to be used through TI provided API.
  [30:28] FSM_ERR_BANK ro — [30:28] Internal. Only to be used through TI provided API.
  [27:24] RESERVED24 ro — [27:24] Internal. Only to be used through TI provided API.
  [23:0] FSM_ERR_ADDR ro — [23:0] Internal. Only to be used through TI provided API.
0x22B0 FSM_PGM_MAXPUL — Internal. Only to be used through TI provided API.
  [31:12] RESERVED12 ro — [31:12] Internal. Only to be used through TI provided API.
  [11:0] FSM_PGM_MAXPUL ro — [11:0] Internal. Only to be used through TI provided API.
0x22B4 FSM_EXECUTE reset 0xA000A — Internal. Only to be used through TI provided API.
  [31:20] RESERVED20 ro — [31:20] Internal. Only to be used through TI provided API.
  [19:16] SUSPEND_NOW — [19:16] Internal. Only to be used through TI provided API.
  [15:5] RESERVED5 ro — [15:5] Internal. Only to be used through TI provided API.
  [4:0] FSMEXECUTE — [4:0] Internal. Only to be used through TI provided API.
0x22B8 EEPROM_CFG reset 0x10000 — Internal. Only to be used through TI provided API.
  [31:0] AUTOSTART_GRACE — [31:0] Internal. Only to be used through TI provided API.
0x22C0 FSM_SECTOR1 reset 0xFFFFFFFF — Internal. Only to be used through TI provided API.
  [31:0] FSM_SECTOR1 — [31:0] Internal. Only to be used through TI provided API.
0x22C4 FSM_SECTOR2 reset 0xFFF — Internal. Only to be used through TI provided API.
  [31:0] FSM_SECTOR2 — [31:0] Internal. Only to be used through TI provided API.
0x22E0 FSM_BSLE0 — Internal. Only to be used through TI provided API.
  [31:0] FSM_BSLE0 — [31:0] Internal. Only to be used through TI provided API.
0x22E4 FSM_BSLE1 — Internal. Only to be used through TI provided API.
  [31:0] FSM_BSL1 — [31:0] Internal. Only to be used through TI provided API.
0x22F0 FSM_BSLP0 — Internal. Only to be used through TI provided API.
  [31:0] FSM_BSLP0 — [31:0] Internal. Only to be used through TI provided API.
0x22F4 FSM_BSLP1 — Internal. Only to be used through TI provided API.
  fields as FSM_BSLE1
0x22F8 FSM_PGM128 — FMC FSM Enable 128-bit Wide Programming
  [0] EN_PGM128 — [0:0] 1: Enables 128-bit wide programming. This mode requires programming supply voltage to be greater than 2.5v at the Flash Pump. The primary use case for this mode is manufacturing test for test time reduction. 0: 64-bit wide programming. Valid at any programming voltage. A 128-bit word is divided into two 64-bit words for programming. [default] This register is write protected with the FSM_WR_ENA register.
0x2400 FCFG_BANK reset 0x801 — Internal. Only to be used through TI provided API.
  [31:20] EE_BANK_WIDTH ro — [31:20] Internal. Only to be used through TI provided API.
  [19:16] EE_NUM_BANK ro — [19:16] Internal. Only to be used through TI provided API.
  [15:4] MAIN_BANK_WIDTH ro — [15:4] Internal. Only to be used through TI provided API.
  [3:0] MAIN_NUM_BANK ro — [3:0] Internal. Only to be used through TI provided API.
0x2404 FCFG_WRAPPER reset 0x60009001 — Internal. Only to be used through TI provided API.
  [31:24] FAMILY_TYPE ro — [31:24] Internal. Only to be used through TI provided API.
  [23:21] RESERVED21 ro — [23:21] Internal. Only to be used through TI provided API.
  [20] MEM_MAP ro — [20:20] Internal. Only to be used through TI provided API.
  [19:16] CPU2 ro — [19:16] Internal. Only to be used through TI provided API.
  [15:12] EE_IN_MAIN ro — [15:12] Internal. Only to be used through TI provided API.
  [11] ROM ro — [11:11] Internal. Only to be used through TI provided API.
  [10] IFLUSH ro — [10:10] Internal. Only to be used through TI provided API.
  [9] SIL3 ro — [9:9] Internal. Only to be used through TI provided API.
  [8] ECCA ro — [8:8] Internal. Only to be used through TI provided API.
  [7:6] AUTO_SUSP ro — [7:6] Internal. Only to be used through TI provided API.
  [5:4] UERR ro — [5:4] Internal. Only to be used through TI provided API.
  [3:0] CPU_TYPE1 ro — [3:0] Internal. Only to be used through TI provided API.
0x2408 FCFG_BNK_TYPE reset 0x4 — Internal. Only to be used through TI provided API.
  [4n+3:4n] B{n}_TYPE ro (n=0..7) — [{4n+3}:{4n}] Internal. Only to be used through TI provided API.
0x2410 FCFG_B0_START reset 0x2000000 — Internal. Only to be used through TI provided API.
  [31:28] B0_MAX_SECTOR ro — [31:28] Internal. Only to be used through TI provided API.
  [27:24] B0_MUX_FACTOR ro — [27:24] Internal. Only to be used through TI provided API.
  [23:0] B0_START_ADDR ro — [23:0] Internal. Only to be used through TI provided API.
{0x2410+4i} FCFG_B{i}_START (i=1..7) — Internal. Only to be used through TI provided API.
  [31:28] B{i}_MAX_SECTOR ro — [31:28] Internal. Only to be used through TI provided API.
  [27:24] B{i}_MUX_FACTOR ro — [27:24] Internal. Only to be used through TI provided API.
  [23:0] B{i}_START_ADDR ro — [23:0] Internal. Only to be used through TI provided API.
0x2430 FCFG_B0_SSIZE0 reset 0x2C0008 — Internal. Only to be used through TI provided API.
  [31:28] RESERVED28 ro — [31:28] Internal. Only to be used through TI provided API.
  [27:16] B0_NUM_SECTORS ro — [27:16] Internal. Only to be used through TI provided API.
  [15:4] RESERVED4 ro — [15:4] Internal. Only to be used through TI provided API.
  [3:0] B0_SECT_SIZE ro — [3:0] Internal. Only to be used through TI provided API.
{0x2434+0x10*i} FCFG_B{i}_SSIZE1 (i=0..7) — Internal. Only to be used through TI provided API.
  [31:0] RESERVED ro — [31:0] Internal. Only to be used through TI provided API.
{0x2438+0x10*i} FCFG_B{i}_SSIZE2 (i=0..7) — Internal. Only to be used through TI provided API.
  fields as FCFG_B0_SSIZE1
{0x243C+0x10*i} FCFG_B{i}_SSIZE3 (i=0..7) — Internal. Only to be used through TI provided API.
  fields as FCFG_B0_SSIZE1
{0x2430+0x10*i} FCFG_B{i}_SSIZE0 (i=1..7) — Internal. Only to be used through TI provided API.
  [31:0] B{i}_SECT_SIZE ro — [31:0] Internal. Only to be used through TI provided API.
